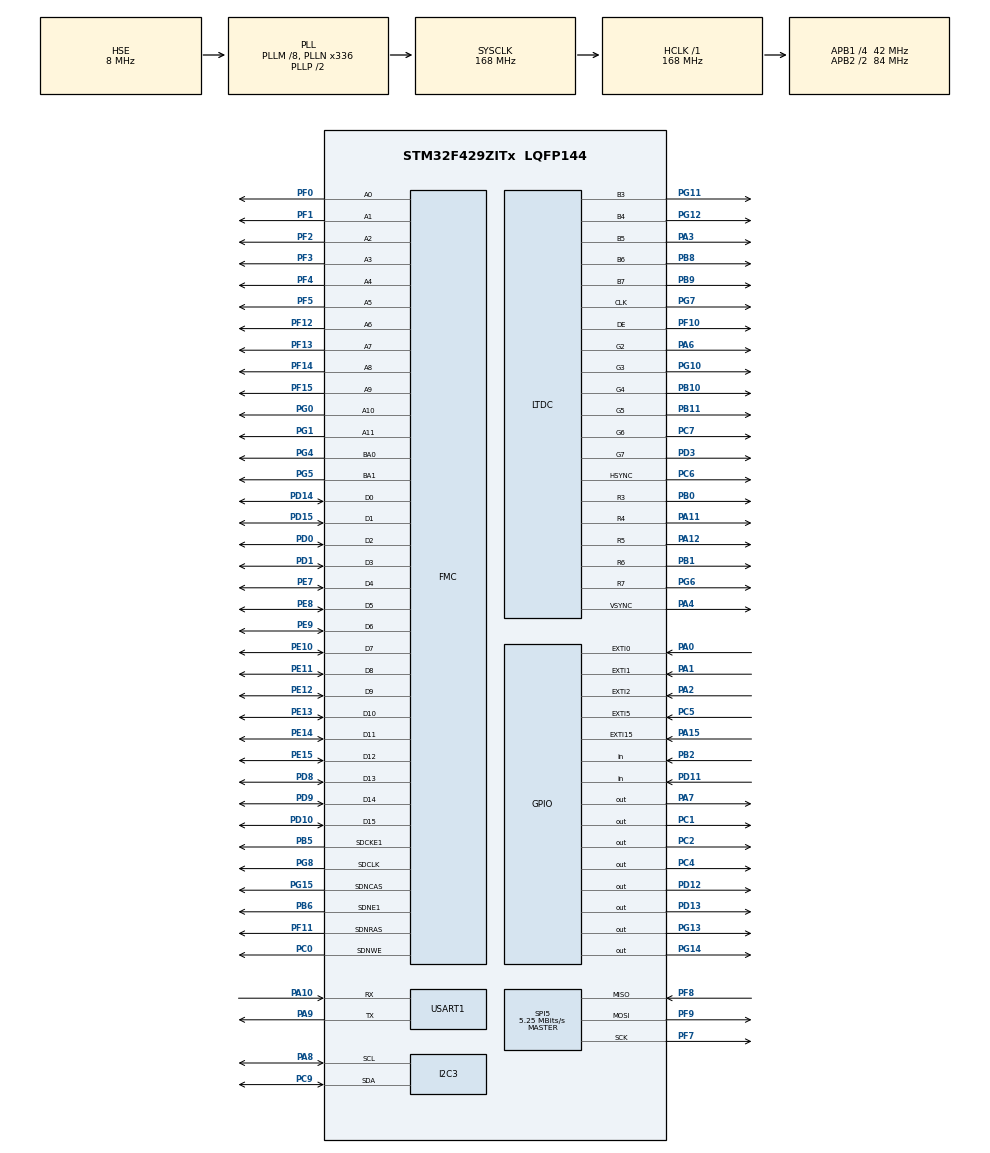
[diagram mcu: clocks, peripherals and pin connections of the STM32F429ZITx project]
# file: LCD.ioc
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DMA2D.ColorMode=DMA2D_OUTPUT_RGB565
FMC.CASLatency1=FMC_SDRAM_CAS_LATENCY_3
FMC.ExitSelfRefreshDelay1=7
FMC.LoadToActiveDelay1=2
FMC.RCDDelay1=2
FMC.RPDelay1=2
FMC.RPDelay2=2
FMC.ReadPipeDelay1=FMC_SDRAM_RPIPE_DELAY_1
FMC.ReadPipeDelay2=FMC_SDRAM_RPIPE_DELAY_1
FMC.RowCycleDelay1=7
FMC.RowCycleDelay2=7
FMC.SDClockPeriod1=FMC_SDRAM_CLOCK_PERIOD_2
FMC.SDClockPeriod2=FMC_SDRAM_CLOCK_PERIOD_2
FMC.SelfRefreshTime1=4
FMC.WriteRecoveryTime1=3
I2C3.Analog_Filter=I2C_ANALOGFILTER_DISABLE
LTDC.ActiveH=320
LTDC.ActiveW=240
LTDC.Alpha_L0=255
LTDC.HBP=20
LTDC.HFP=10
LTDC.HSync=10
LTDC.ImageHeight_L0=320
LTDC.ImageWidth_L0=240
LTDC.Layers=0
LTDC.PixelFormat_L0=LTDC_PIXEL_FORMAT_RGB565
LTDC.PixelFormat_L1=LTDC_PIXEL_FORMAT_RGB565
LTDC.VFP=4
LTDC.VSync=2
LTDC.WindowX0_L0=0
LTDC.WindowX1_L0=240
LTDC.WindowY0_L0=0
LTDC.WindowY1_L0=320
Mcu.Family=STM32F4
Mcu.Name=STM32F429ZITx
Mcu.Package=LQFP144
NVIC.DMA2D_IRQn=true\:0\:0\:false\:false\:true\:true\:true
NVIC.LTDC_IRQn=true\:0\:0\:false\:false\:true\:true\:true
NVIC.PriorityGroup=NVIC_PRIORITYGROUP_4
NVIC.TIM6_DAC_IRQn=true\:0\:0\:false\:false\:true\:false\:true
NVIC.TimeBase=TIM6_DAC_IRQn
NVIC.TimeBaseIP=TIM6
NVIC.USART1_IRQn=true\:0\:0\:false\:false\:true\:true\:true
PA0/WKUP.GPIO_ModeDefaultEXTI=GPIO_MODE_IT_RISING
PA0/WKUP.GPIO_PuPd=GPIO_NOPULL
PA0/WKUP.Signal=GPXTI0
PA1.GPIO_ModeDefaultEXTI=GPIO_MODE_IT_RISING
PA1.GPIO_PuPd=GPIO_NOPULL
PA1.Signal=GPXTI1
PA10.GPIO_ModeDefaultPP=GPIO_MODE_AF_PP
PA10.GPIO_PuPd=GPIO_NOPULL
PA10.GPIO_Speed=GPIO_SPEED_FREQ_VERY_HIGH
PA10.Mode=Asynchronous
PA10.Signal=USART1_RX
PA11.GPIO_Mode=GPIO_MODE_AF_PP
PA11.GPIO_PuPd=GPIO_NOPULL
PA11.GPIO_Speed=GPIO_SPEED_FREQ_LOW
PA11.Mode=RGB565
PA11.Signal=LTDC_R4
PA12.GPIO_Mode=GPIO_MODE_AF_PP
PA12.GPIO_PuPd=GPIO_NOPULL
PA12.GPIO_Speed=GPIO_SPEED_FREQ_LOW
PA12.Mode=RGB565
PA12.Signal=LTDC_R5
PA13.Signal=SYS_JTMS-SWDIO
PA14.Signal=SYS_JTCK-SWCLK
PA15.GPIO_ModeDefaultEXTI=GPIO_MODE_IT_RISING
PA15.GPIO_PuPd=GPIO_NOPULL
PA15.Signal=GPXTI15
PA2.GPIO_ModeDefaultEXTI=GPIO_MODE_IT_RISING
PA2.GPIO_PuPd=GPIO_NOPULL
PA2.Signal=GPXTI2
PA3.GPIO_Mode=GPIO_MODE_AF_PP
PA3.GPIO_PuPd=GPIO_NOPULL
PA3.GPIO_Speed=GPIO_SPEED_FREQ_LOW
PA3.Mode=RGB565
PA3.Signal=LTDC_B5
PA4.GPIO_Mode=GPIO_MODE_AF_PP
PA4.GPIO_PuPd=GPIO_NOPULL
PA4.GPIO_Speed=GPIO_SPEED_FREQ_LOW
PA4.Mode=RGB565
PA4.Signal=LTDC_VSYNC
PA6.GPIO_Mode=GPIO_MODE_AF_PP
PA6.GPIO_PuPd=GPIO_NOPULL
PA6.GPIO_Speed=GPIO_SPEED_FREQ_LOW
PA6.Mode=RGB565
PA6.Signal=LTDC_G2
PA7.GPIO_Mode=GPIO_MODE_OUTPUT_PP
PA7.GPIO_ModeDefaultOutputPP=GPIO_MODE_OUTPUT_PP
PA7.GPIO_PuPd=GPIO_NOPULL
PA7.GPIO_Speed=GPIO_SPEED_FREQ_LOW
PA7.PinState=GPIO_PIN_RESET
PA7.Signal=GPIO_Output
PA8.GPIO_Mode=GPIO_MODE_AF_OD
PA8.GPIO_PuPd=GPIO_NOPULL
PA8.GPIO_PuPdOD=GPIO_PULLUP
PA8.GPIO_Speed=GPIO_SPEED_FREQ_VERY_HIGH
PA8.Mode=I2C
PA8.Signal=I2C3_SCL
PA9.GPIO_ModeDefaultPP=GPIO_MODE_AF_PP
PA9.GPIO_PuPd=GPIO_NOPULL
PA9.GPIO_Speed=GPIO_SPEED_FREQ_VERY_HIGH
PA9.Mode=Asynchronous
PA9.Signal=USART1_TX
PB0.GPIO_Mode=GPIO_MODE_AF_PP
PB0.GPIO_PuPd=GPIO_NOPULL
PB0.GPIO_Speed=GPIO_SPEED_FREQ_LOW
PB0.Mode=RGB565
PB0.Signal=LTDC_R3
PB1.GPIO_Mode=GPIO_MODE_AF_PP
PB1.GPIO_PuPd=GPIO_NOPULL
PB1.GPIO_Speed=GPIO_SPEED_FREQ_LOW
PB1.Mode=RGB565
PB1.Signal=LTDC_R6
PB10.GPIO_Mode=GPIO_MODE_AF_PP
PB10.GPIO_PuPd=GPIO_NOPULL
PB10.GPIO_Speed=GPIO_SPEED_FREQ_LOW
PB10.Mode=RGB565
PB10.Signal=LTDC_G4
PB11.GPIO_Mode=GPIO_MODE_AF_PP
PB11.GPIO_PuPd=GPIO_NOPULL
PB11.GPIO_Speed=GPIO_SPEED_FREQ_LOW
PB11.Mode=RGB565
PB11.Signal=LTDC_G5
PB12.GPIO_Mode=GPIO_MODE_AF_PP
PB12.GPIO_PuPd=GPIO_NOPULL
PB12.GPIO_Speed=GPIO_SPEED_FREQ_VERY_HIGH
PB12.Signal=USB_OTG_HS_ID
PB13.GPIO_Mode=GPIO_MODE_INPUT
PB13.GPIO_PuPd=GPIO_NOPULL
PB13.Signal=USB_OTG_HS_VBUS
PB14.GPIO_Mode=GPIO_MODE_AF_PP
PB14.GPIO_PuPd=GPIO_NOPULL
PB14.GPIO_Speed=GPIO_SPEED_FREQ_VERY_HIGH
PB14.Signal=USB_OTG_HS_DM
PB15.GPIO_Mode=GPIO_MODE_AF_PP
PB15.GPIO_PuPd=GPIO_NOPULL
PB15.GPIO_Speed=GPIO_SPEED_FREQ_VERY_HIGH
PB15.Signal=USB_OTG_HS_DP
PB2/BOOT1.GPIO_Mode=GPIO_MODE_INPUT
PB2/BOOT1.GPIO_PuPd=GPIO_NOPULL
PB2/BOOT1.Signal=GPIO_Input
PB5.GPIO_Mode=GPIO_MODE_AF_PP
PB5.GPIO_PuPd=GPIO_NOPULL
PB5.GPIO_Speed=GPIO_SPEED_FREQ_VERY_HIGH
PB5.GPIO_Speed_High_Default=GPIO_SPEED_FREQ_VERY_HIGH
PB5.Mode=SdramChipSelect2_1
PB5.Signal=FMC_SDCKE1
PB6.GPIO_Mode=GPIO_MODE_AF_PP
PB6.GPIO_PuPd=GPIO_NOPULL
PB6.GPIO_Speed=GPIO_SPEED_FREQ_VERY_HIGH
PB6.GPIO_Speed_High_Default=GPIO_SPEED_FREQ_VERY_HIGH
PB6.Mode=SdramChipSelect2_1
PB6.Signal=FMC_SDNE1
PB8.GPIO_Mode=GPIO_MODE_AF_PP
PB8.GPIO_PuPd=GPIO_NOPULL
PB8.GPIO_Speed=GPIO_SPEED_FREQ_LOW
PB8.Mode=RGB565
PB8.Signal=LTDC_B6
PB9.GPIO_Mode=GPIO_MODE_AF_PP
PB9.GPIO_PuPd=GPIO_NOPULL
PB9.GPIO_Speed=GPIO_SPEED_FREQ_LOW
PB9.Mode=RGB565
PB9.Signal=LTDC_B7
PC0.GPIO_Mode=GPIO_MODE_AF_PP
PC0.GPIO_PuPd=GPIO_NOPULL
PC0.GPIO_Speed=GPIO_SPEED_FREQ_VERY_HIGH
PC0.GPIO_Speed_High_Default=GPIO_SPEED_FREQ_VERY_HIGH
PC0.Signal=FMC_SDNWE
PC1.GPIO_Mode=GPIO_MODE_OUTPUT_PP
PC1.GPIO_ModeDefaultOutputPP=GPIO_MODE_OUTPUT_PP
PC1.GPIO_PuPd=GPIO_NOPULL
PC1.GPIO_Speed=GPIO_SPEED_FREQ_LOW
PC1.PinState=GPIO_PIN_RESET
PC1.Signal=GPIO_Output
PC10.GPIO_Mode=GPIO_MODE_AF_PP
PC10.GPIO_PuPd=GPIO_NOPULL
PC10.GPIO_Speed=GPIO_SPEED_FREQ_LOW
PC10.Signal=LTDC_R2
PC14/OSC32_IN.Signal=RCC_OSC32_IN
PC15/OSC32_OUT.Signal=RCC_OSC32_OUT
PC2.GPIO_Mode=GPIO_MODE_OUTPUT_PP
PC2.GPIO_ModeDefaultOutputPP=GPIO_MODE_OUTPUT_PP
PC2.GPIO_PuPd=GPIO_NOPULL
PC2.GPIO_Speed=GPIO_SPEED_FREQ_LOW
PC2.PinState=GPIO_PIN_RESET
PC2.Signal=GPIO_Output
PC4.GPIO_Mode=GPIO_MODE_OUTPUT_PP
PC4.GPIO_ModeDefaultOutputPP=GPIO_MODE_OUTPUT_PP
PC4.GPIO_PuPd=GPIO_NOPULL
PC4.GPIO_Speed=GPIO_SPEED_FREQ_LOW
PC4.PinState=GPIO_PIN_RESET
PC4.Signal=GPIO_Output
PC5.GPIO_ModeDefaultEXTI=GPIO_MODE_IT_RISING
PC5.GPIO_PuPd=GPIO_NOPULL
PC5.Signal=GPXTI5
PC6.GPIO_Mode=GPIO_MODE_AF_PP
PC6.GPIO_PuPd=GPIO_NOPULL
PC6.GPIO_Speed=GPIO_SPEED_FREQ_LOW
PC6.Mode=RGB565
PC6.Signal=LTDC_HSYNC
PC7.GPIO_Mode=GPIO_MODE_AF_PP
PC7.GPIO_PuPd=GPIO_NOPULL
PC7.GPIO_Speed=GPIO_SPEED_FREQ_LOW
PC7.Mode=RGB565
PC7.Signal=LTDC_G6
PC9.GPIO_Mode=GPIO_MODE_AF_OD
PC9.GPIO_PuPd=GPIO_NOPULL
PC9.GPIO_PuPdOD=GPIO_PULLUP
PC9.GPIO_Speed=GPIO_SPEED_FREQ_VERY_HIGH
PC9.Mode=I2C
PC9.Signal=I2C3_SDA
PD0.GPIO_Mode=GPIO_MODE_AF_PP
PD0.GPIO_PuPd=GPIO_NOPULL
PD0.GPIO_Speed=GPIO_SPEED_FREQ_VERY_HIGH
PD0.GPIO_Speed_High_Default=GPIO_SPEED_FREQ_VERY_HIGH
PD0.Signal=FMC_D2_DA2
PD1.GPIO_Mode=GPIO_MODE_AF_PP
PD1.GPIO_PuPd=GPIO_NOPULL
PD1.GPIO_Speed=GPIO_SPEED_FREQ_VERY_HIGH
PD1.GPIO_Speed_High_Default=GPIO_SPEED_FREQ_VERY_HIGH
PD1.Signal=FMC_D3_DA3
PD10.GPIO_Mode=GPIO_MODE_AF_PP
PD10.GPIO_PuPd=GPIO_NOPULL
PD10.GPIO_Speed=GPIO_SPEED_FREQ_VERY_HIGH
PD10.GPIO_Speed_High_Default=GPIO_SPEED_FREQ_VERY_HIGH
PD10.Signal=FMC_D15_DA15
PD11.GPIO_Mode=GPIO_MODE_INPUT
PD11.GPIO_PuPd=GPIO_NOPULL
PD11.Signal=GPIO_Input
PD12.GPIO_Mode=GPIO_MODE_OUTPUT_PP
PD12.GPIO_ModeDefaultOutputPP=GPIO_MODE_OUTPUT_PP
PD12.GPIO_PuPd=GPIO_NOPULL
PD12.GPIO_Speed=GPIO_SPEED_FREQ_LOW
PD12.PinState=GPIO_PIN_RESET
PD12.Signal=GPIO_Output
PD13.GPIO_Mode=GPIO_MODE_OUTPUT_PP
PD13.GPIO_ModeDefaultOutputPP=GPIO_MODE_OUTPUT_PP
PD13.GPIO_PuPd=GPIO_NOPULL
PD13.GPIO_Speed=GPIO_SPEED_FREQ_LOW
PD13.PinState=GPIO_PIN_RESET
PD13.Signal=GPIO_Output
PD14.GPIO_Mode=GPIO_MODE_AF_PP
PD14.GPIO_PuPd=GPIO_NOPULL
PD14.GPIO_Speed=GPIO_SPEED_FREQ_VERY_HIGH
PD14.GPIO_Speed_High_Default=GPIO_SPEED_FREQ_VERY_HIGH
PD14.Signal=FMC_D0_DA0
PD15.GPIO_Mode=GPIO_MODE_AF_PP
PD15.GPIO_PuPd=GPIO_NOPULL
PD15.GPIO_Speed=GPIO_SPEED_FREQ_VERY_HIGH
PD15.GPIO_Speed_High_Default=GPIO_SPEED_FREQ_VERY_HIGH
PD15.Signal=FMC_D1_DA1
PD3.GPIO_Mode=GPIO_MODE_AF_PP
PD3.GPIO_PuPd=GPIO_NOPULL
PD3.GPIO_Speed=GPIO_SPEED_FREQ_LOW
PD3.Mode=RGB565
PD3.Signal=LTDC_G7
PD6.GPIO_Mode=GPIO_MODE_AF_PP
PD6.GPIO_PuPd=GPIO_NOPULL
PD6.GPIO_Speed=GPIO_SPEED_FREQ_LOW
PD6.Signal=LTDC_B2
PD8.GPIO_Mode=GPIO_MODE_AF_PP
PD8.GPIO_PuPd=GPIO_NOPULL
PD8.GPIO_Speed=GPIO_SPEED_FREQ_VERY_HIGH
PD8.GPIO_Speed_High_Default=GPIO_SPEED_FREQ_VERY_HIGH
PD8.Signal=FMC_D13_DA13
PD9.GPIO_Mode=GPIO_MODE_AF_PP
PD9.GPIO_PuPd=GPIO_NOPULL
PD9.GPIO_Speed=GPIO_SPEED_FREQ_VERY_HIGH
PD9.GPIO_Speed_High_Default=GPIO_SPEED_FREQ_VERY_HIGH
PD9.Signal=FMC_D14_DA14
PE0.GPIO_Mode=GPIO_MODE_AF_PP
PE0.GPIO_PuPd=GPIO_NOPULL
PE0.GPIO_Speed=GPIO_SPEED_FREQ_VERY_HIGH
PE0.GPIO_Speed_High_Default=GPIO_SPEED_FREQ_VERY_HIGH
PE0.Signal=FMC_NBL0
PE1.GPIO_Mode=GPIO_MODE_AF_PP
PE1.GPIO_PuPd=GPIO_NOPULL
PE1.GPIO_Speed=GPIO_SPEED_FREQ_VERY_HIGH
PE1.GPIO_Speed_High_Default=GPIO_SPEED_FREQ_VERY_HIGH
PE1.Signal=FMC_NBL1
PE10.GPIO_Mode=GPIO_MODE_AF_PP
PE10.GPIO_PuPd=GPIO_NOPULL
PE10.GPIO_Speed=GPIO_SPEED_FREQ_VERY_HIGH
PE10.GPIO_Speed_High_Default=GPIO_SPEED_FREQ_VERY_HIGH
PE10.Signal=FMC_D7_DA7
PE11.GPIO_Mode=GPIO_MODE_AF_PP
PE11.GPIO_PuPd=GPIO_NOPULL
PE11.GPIO_Speed=GPIO_SPEED_FREQ_VERY_HIGH
PE11.GPIO_Speed_High_Default=GPIO_SPEED_FREQ_VERY_HIGH
PE11.Signal=FMC_D8_DA8
PE12.GPIO_Mode=GPIO_MODE_AF_PP
PE12.GPIO_PuPd=GPIO_NOPULL
PE12.GPIO_Speed=GPIO_SPEED_FREQ_VERY_HIGH
PE12.GPIO_Speed_High_Default=GPIO_SPEED_FREQ_VERY_HIGH
PE12.Signal=FMC_D9_DA9
PE13.GPIO_Mode=GPIO_MODE_AF_PP
PE13.GPIO_PuPd=GPIO_NOPULL
PE13.GPIO_Speed=GPIO_SPEED_FREQ_VERY_HIGH
PE13.GPIO_Speed_High_Default=GPIO_SPEED_FREQ_VERY_HIGH
PE13.Signal=FMC_D10_DA10
PE14.GPIO_Mode=GPIO_MODE_AF_PP
PE14.GPIO_PuPd=GPIO_NOPULL
PE14.GPIO_Speed=GPIO_SPEED_FREQ_VERY_HIGH
PE14.GPIO_Speed_High_Default=GPIO_SPEED_FREQ_VERY_HIGH
PE14.Signal=FMC_D11_DA11
PE15.GPIO_Mode=GPIO_MODE_AF_PP
PE15.GPIO_PuPd=GPIO_NOPULL
PE15.GPIO_Speed=GPIO_SPEED_FREQ_VERY_HIGH
PE15.GPIO_Speed_High_Default=GPIO_SPEED_FREQ_VERY_HIGH
PE15.Signal=FMC_D12_DA12
PE7.GPIO_Mode=GPIO_MODE_AF_PP
PE7.GPIO_PuPd=GPIO_NOPULL
PE7.GPIO_Speed=GPIO_SPEED_FREQ_VERY_HIGH
PE7.GPIO_Speed_High_Default=GPIO_SPEED_FREQ_VERY_HIGH
PE7.Signal=FMC_D4_DA4
PE8.GPIO_Mode=GPIO_MODE_AF_PP
PE8.GPIO_PuPd=GPIO_NOPULL
PE8.GPIO_Speed=GPIO_SPEED_FREQ_VERY_HIGH
PE8.GPIO_Speed_High_Default=GPIO_SPEED_FREQ_VERY_HIGH
PE8.Signal=FMC_D5_DA5
PE9.GPIO_Mode=GPIO_MODE_AF_PP
PE9.GPIO_PuPd=GPIO_NOPULL
PE9.GPIO_Speed=GPIO_SPEED_FREQ_VERY_HIGH
PE9.GPIO_Speed_High_Default=GPIO_SPEED_FREQ_VERY_HIGH
PE9.Signal=FMC_D6_DA6
PF0.GPIO_Mode=GPIO_MODE_AF_PP
PF0.GPIO_PuPd=GPIO_NOPULL
PF0.GPIO_Speed=GPIO_SPEED_FREQ_VERY_HIGH
PF0.GPIO_Speed_High_Default=GPIO_SPEED_FREQ_VERY_HIGH
PF0.Signal=FMC_A0
PF1.GPIO_Mode=GPIO_MODE_AF_PP
PF1.GPIO_PuPd=GPIO_NOPULL
PF1.GPIO_Speed=GPIO_SPEED_FREQ_VERY_HIGH
PF1.GPIO_Speed_High_Default=GPIO_SPEED_FREQ_VERY_HIGH
PF1.Signal=FMC_A1
PF10.GPIO_Mode=GPIO_MODE_AF_PP
PF10.GPIO_PuPd=GPIO_NOPULL
PF10.GPIO_Speed=GPIO_SPEED_FREQ_LOW
PF10.Mode=RGB565
PF10.Signal=LTDC_DE
PF11.GPIO_Mode=GPIO_MODE_AF_PP
PF11.GPIO_PuPd=GPIO_NOPULL
PF11.GPIO_Speed=GPIO_SPEED_FREQ_VERY_HIGH
PF11.GPIO_Speed_High_Default=GPIO_SPEED_FREQ_VERY_HIGH
PF11.Signal=FMC_SDNRAS
PF12.GPIO_Mode=GPIO_MODE_AF_PP
PF12.GPIO_PuPd=GPIO_NOPULL
PF12.GPIO_Speed=GPIO_SPEED_FREQ_VERY_HIGH
PF12.GPIO_Speed_High_Default=GPIO_SPEED_FREQ_VERY_HIGH
PF12.Signal=FMC_A6
PF13.GPIO_Mode=GPIO_MODE_AF_PP
PF13.GPIO_PuPd=GPIO_NOPULL
PF13.GPIO_Speed=GPIO_SPEED_FREQ_VERY_HIGH
PF13.GPIO_Speed_High_Default=GPIO_SPEED_FREQ_VERY_HIGH
PF13.Signal=FMC_A7
PF14.GPIO_Mode=GPIO_MODE_AF_PP
PF14.GPIO_PuPd=GPIO_NOPULL
PF14.GPIO_Speed=GPIO_SPEED_FREQ_VERY_HIGH
PF14.GPIO_Speed_High_Default=GPIO_SPEED_FREQ_VERY_HIGH
PF14.Signal=FMC_A8
PF15.GPIO_Mode=GPIO_MODE_AF_PP
PF15.GPIO_PuPd=GPIO_NOPULL
PF15.GPIO_Speed=GPIO_SPEED_FREQ_VERY_HIGH
PF15.GPIO_Speed_High_Default=GPIO_SPEED_FREQ_VERY_HIGH
PF15.Signal=FMC_A9
PF2.GPIO_Mode=GPIO_MODE_AF_PP
PF2.GPIO_PuPd=GPIO_NOPULL
PF2.GPIO_Speed=GPIO_SPEED_FREQ_VERY_HIGH
PF2.GPIO_Speed_High_Default=GPIO_SPEED_FREQ_VERY_HIGH
PF2.Signal=FMC_A2
PF3.GPIO_Mode=GPIO_MODE_AF_PP
PF3.GPIO_PuPd=GPIO_NOPULL
PF3.GPIO_Speed=GPIO_SPEED_FREQ_VERY_HIGH
PF3.GPIO_Speed_High_Default=GPIO_SPEED_FREQ_VERY_HIGH
PF3.Signal=FMC_A3
PF4.GPIO_Mode=GPIO_MODE_AF_PP
PF4.GPIO_PuPd=GPIO_NOPULL
PF4.GPIO_Speed=GPIO_SPEED_FREQ_VERY_HIGH
PF4.GPIO_Speed_High_Default=GPIO_SPEED_FREQ_VERY_HIGH
PF4.Signal=FMC_A4
PF5.GPIO_Mode=GPIO_MODE_AF_PP
PF5.GPIO_PuPd=GPIO_NOPULL
PF5.GPIO_Speed=GPIO_SPEED_FREQ_VERY_HIGH
PF5.GPIO_Speed_High_Default=GPIO_SPEED_FREQ_VERY_HIGH
PF5.Signal=FMC_A5
PF7.GPIO_Mode=GPIO_MODE_AF_PP
PF7.GPIO_PuPd=GPIO_NOPULL
PF7.GPIO_Speed=GPIO_SPEED_FREQ_VERY_HIGH
PF7.Mode=Full_Duplex_Master
PF7.Signal=SPI5_SCK
PF8.GPIO_Mode=GPIO_MODE_AF_PP
PF8.GPIO_PuPd=GPIO_NOPULL
PF8.GPIO_Speed=GPIO_SPEED_FREQ_VERY_HIGH
PF8.Mode=Full_Duplex_Master
PF8.Signal=SPI5_MISO
PF9.GPIO_Mode=GPIO_MODE_AF_PP
PF9.GPIO_PuPd=GPIO_NOPULL
PF9.GPIO_Speed=GPIO_SPEED_FREQ_VERY_HIGH
PF9.Mode=Full_Duplex_Master
PF9.Signal=SPI5_MOSI
PG0.GPIO_Mode=GPIO_MODE_AF_PP
PG0.GPIO_PuPd=GPIO_NOPULL
PG0.GPIO_Speed=GPIO_SPEED_FREQ_VERY_HIGH
PG0.GPIO_Speed_High_Default=GPIO_SPEED_FREQ_VERY_HIGH
PG0.Signal=FMC_A10
PG1.GPIO_Mode=GPIO_MODE_AF_PP
PG1.GPIO_PuPd=GPIO_NOPULL
PG1.GPIO_Speed=GPIO_SPEED_FREQ_VERY_HIGH
PG1.GPIO_Speed_High_Default=GPIO_SPEED_FREQ_VERY_HIGH
PG1.Signal=FMC_A11
PG10.GPIO_Mode=GPIO_MODE_AF_PP
PG10.GPIO_PuPd=GPIO_NOPULL
PG10.GPIO_Speed=GPIO_SPEED_FREQ_LOW
PG10.Mode=RGB565
PG10.Signal=LTDC_G3
PG11.GPIO_Mode=GPIO_MODE_AF_PP
PG11.GPIO_PuPd=GPIO_NOPULL
PG11.GPIO_Speed=GPIO_SPEED_FREQ_LOW
PG11.Mode=RGB565
PG11.Signal=LTDC_B3
PG12.GPIO_Mode=GPIO_MODE_AF_PP
PG12.GPIO_PuPd=GPIO_NOPULL
PG12.GPIO_Speed=GPIO_SPEED_FREQ_LOW
PG12.Mode=RGB565
PG12.Signal=LTDC_B4
PG13.GPIO_Mode=GPIO_MODE_OUTPUT_PP
PG13.GPIO_ModeDefaultOutputPP=GPIO_MODE_OUTPUT_PP
PG13.GPIO_PuPd=GPIO_NOPULL
PG13.GPIO_Speed=GPIO_SPEED_FREQ_LOW
PG13.PinState=GPIO_PIN_RESET
PG13.Signal=GPIO_Output
PG14.GPIO_Mode=GPIO_MODE_OUTPUT_PP
PG14.GPIO_ModeDefaultOutputPP=GPIO_MODE_OUTPUT_PP
PG14.GPIO_PuPd=GPIO_NOPULL
PG14.GPIO_Speed=GPIO_SPEED_FREQ_LOW
PG14.PinState=GPIO_PIN_RESET
PG14.Signal=GPIO_Output
PG15.GPIO_Mode=GPIO_MODE_AF_PP
PG15.GPIO_PuPd=GPIO_NOPULL
PG15.GPIO_Speed=GPIO_SPEED_FREQ_VERY_HIGH
PG15.GPIO_Speed_High_Default=GPIO_SPEED_FREQ_VERY_HIGH
PG15.Signal=FMC_SDNCAS
PG4.GPIO_Mode=GPIO_MODE_AF_PP
PG4.GPIO_PuPd=GPIO_NOPULL
PG4.GPIO_Speed=GPIO_SPEED_FREQ_VERY_HIGH
PG4.GPIO_Speed_High_Default=GPIO_SPEED_FREQ_VERY_HIGH
PG4.Signal=FMC_A14_BA0
PG5.GPIO_Mode=GPIO_MODE_AF_PP
PG5.GPIO_PuPd=GPIO_NOPULL
PG5.GPIO_Speed=GPIO_SPEED_FREQ_VERY_HIGH
PG5.GPIO_Speed_High_Default=GPIO_SPEED_FREQ_VERY_HIGH
PG5.Signal=FMC_A15_BA1
PG6.GPIO_Mode=GPIO_MODE_AF_PP
PG6.GPIO_PuPd=GPIO_NOPULL
PG6.GPIO_Speed=GPIO_SPEED_FREQ_LOW
PG6.Mode=RGB565
PG6.Signal=LTDC_R7
PG7.GPIO_Mode=GPIO_MODE_AF_PP
PG7.GPIO_PuPd=GPIO_NOPULL
PG7.GPIO_Speed=GPIO_SPEED_FREQ_LOW
PG7.Mode=RGB565
PG7.Signal=LTDC_CLK
PG8.GPIO_Mode=GPIO_MODE_AF_PP
PG8.GPIO_PuPd=GPIO_NOPULL
PG8.GPIO_Speed=GPIO_SPEED_FREQ_VERY_HIGH
PG8.GPIO_Speed_High_Default=GPIO_SPEED_FREQ_VERY_HIGH
PG8.Signal=FMC_SDCLK
PH0/OSC_IN.Mode=HSE-External-Oscillator
PH0/OSC_IN.Signal=RCC_OSC_IN
PH1/OSC_OUT.Mode=HSE-External-Oscillator
PH1/OSC_OUT.Signal=RCC_OSC_OUT
ProjectManager.HeapSize=0x200
ProjectManager.StackSize=0x400
ProjectManager.TargetToolchain=MDK-ARM V5.27
RCC.48MHZClocksFreq_Value=67200000
RCC.AHBFreq_Value=168000000
RCC.APB1CLKDivider=RCC_HCLK_DIV4
RCC.APB1Freq_Value=42000000
RCC.APB1TimFreq_Value=84000000
RCC.APB2CLKDivider=RCC_HCLK_DIV2
RCC.APB2Freq_Value=84000000
RCC.APB2TimFreq_Value=168000000
RCC.CortexFreq_Value=168000000
RCC.HCLKFreq_Value=168000000
RCC.HSE_VALUE=8000000
RCC.HSI_VALUE=16000000
RCC.LSE_VALUE=32768
RCC.PLLM=8
RCC.PLLN=336
RCC.PLLQ=5
RCC.PLLSAIN=192
RCC.PLLSourceVirtual=RCC_PLLSOURCE_HSE
RCC.SYSCLKFreq_VALUE=168000000
RCC.SYSCLKSource=RCC_SYSCLKSOURCE_PLLCLK
RCC.VCOOutputFreq_Value=336000000
SH.FMC_A0.0=FMC_A0,12b-sda1
SH.FMC_A1.0=FMC_A1,12b-sda1
SH.FMC_A10.0=FMC_A10,12b-sda1
SH.FMC_A11.0=FMC_A11,12b-sda1
SH.FMC_A14_BA0.0=FMC_BA0,FourSdramBanks1
SH.FMC_A15_BA1.0=FMC_BA1,FourSdramBanks1
SH.FMC_A2.0=FMC_A2,12b-sda1
SH.FMC_A3.0=FMC_A3,12b-sda1
SH.FMC_A4.0=FMC_A4,12b-sda1
SH.FMC_A5.0=FMC_A5,12b-sda1
SH.FMC_A6.0=FMC_A6,12b-sda1
SH.FMC_A7.0=FMC_A7,12b-sda1
SH.FMC_A8.0=FMC_A8,12b-sda1
SH.FMC_A9.0=FMC_A9,12b-sda1
SH.FMC_D0_DA0.0=FMC_D0,sd-16b-d1
SH.FMC_D10_DA10.0=FMC_D10,sd-16b-d1
SH.FMC_D11_DA11.0=FMC_D11,sd-16b-d1
SH.FMC_D12_DA12.0=FMC_D12,sd-16b-d1
SH.FMC_D13_DA13.0=FMC_D13,sd-16b-d1
SH.FMC_D14_DA14.0=FMC_D14,sd-16b-d1
SH.FMC_D15_DA15.0=FMC_D15,sd-16b-d1
SH.FMC_D1_DA1.0=FMC_D1,sd-16b-d1
SH.FMC_D2_DA2.0=FMC_D2,sd-16b-d1
SH.FMC_D3_DA3.0=FMC_D3,sd-16b-d1
SH.FMC_D4_DA4.0=FMC_D4,sd-16b-d1
SH.FMC_D5_DA5.0=FMC_D5,sd-16b-d1
SH.FMC_D6_DA6.0=FMC_D6,sd-16b-d1
SH.FMC_D7_DA7.0=FMC_D7,sd-16b-d1
SH.FMC_D8_DA8.0=FMC_D8,sd-16b-d1
SH.FMC_D9_DA9.0=FMC_D9,sd-16b-d1
SH.FMC_NBL0.0=FMC_NBL0
SH.FMC_NBL1.0=FMC_NBL1
SH.FMC_SDCLK.0=FMC_SDCLK,12b-sda1
SH.FMC_SDNCAS.0=FMC_SDNCAS,12b-sda1
SH.FMC_SDNRAS.0=FMC_SDNRAS,12b-sda1
SH.FMC_SDNWE.0=FMC_SDNWE,12b-sda1
SPI5.BaudRatePrescaler=SPI_BAUDRATEPRESCALER_16
SPI5.CalculateBaudRate=5.25 MBits/s
SPI5.Direction=SPI_DIRECTION_2LINES
SPI5.Mode=SPI_MODE_MASTER
SPI5.VirtualType=VM_MASTER
USART1.VirtualMode=VM_ASYNC
VP_DMA2D_VS_DMA2D.Mode=DMA2D_Activate
VP_SYS_VS_tim6.Mode=TIM6
VP_TIM1_VS_ClockSourceINT.Mode=Internal
board=STM32F429I-DISC1

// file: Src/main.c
/* USER CODE BEGIN Header */
/**
  ******************************************************************************
  * @file           : main.c
  * @brief          : Main program body
  ******************************************************************************
  * @attention
  *
  * <h2><center>&copy; Copyright (c) 2020 STMicroelectronics.
  * All rights reserved.</center></h2>
  *
  * This software component is licensed by ST under Ultimate Liberty license
  * SLA0044, the "License"; You may not use this file except in compliance with
  * the License. You may obtain a copy of the License at:
  *                             www.st.com/SLA0044
  *
  ******************************************************************************
  */
/* USER CODE END Header */

#include "main.h"

/* USER CODE BEGIN Includes */
#include "stm32f429i_discovery_lcd.h"
#include "stm32f429i_discovery_sdram.h"
#include "stm32f429i_discovery_ts.h"
#include "stlogo.h"
#include "usv.h"
#include "tic_tac_toe.h"
#include <stdio.h>
#include <string.h>

/* USER CODE END Includes */

DMA2D_HandleTypeDef hdma2d;

I2C_HandleTypeDef hi2c3;

LTDC_HandleTypeDef hltdc;

SPI_HandleTypeDef hspi5;

TIM_HandleTypeDef htim1;

UART_HandleTypeDef huart1;

SDRAM_HandleTypeDef hsdram1;

void SystemClock_Config(void);
static void MX_GPIO_Init(void);
static void MX_DMA2D_Init(void);
static void MX_FMC_Init(void);
static void MX_I2C3_Init(void);
static void MX_LTDC_Init(void);
static void MX_SPI5_Init(void);
static void MX_TIM1_Init(void);
static void MX_USART1_UART_Init(void);

#include "stm32f429i_discovery_lcd.h"
#include "stm32f429i_discovery_sdram.h"
#define NUMAR_X 0
#define NUMAR_0 1
#define NO_PLAYER -1
int tryGetWinner(int board[3][3]);
void showGameScreen();
void Meniu_Credits();
void Meniu_Show();

int main(void)
{
  HAL_Init();
  SystemClock_Config();
  MX_GPIO_Init();
  MX_DMA2D_Init();
  MX_FMC_Init();
  MX_I2C3_Init();
  MX_LTDC_Init();
  MX_SPI5_Init();
  MX_TIM1_Init();
  MX_USART1_UART_Init();
	printf("\n\rLaborator-Proiect MICROCONTROLERE\n\r");
	BSP_LCD_Init();
  BSP_LCD_LayerDefaultInit(LCD_BACKGROUND_LAYER, LCD_FRAME_BUFFER);
	BSP_LCD_LayerDefaultInit(LCD_FOREGROUND_LAYER, LCD_FRAME_BUFFER);
  BSP_LCD_SelectLayer(LCD_FOREGROUND_LAYER);
  BSP_LCD_DisplayOn();
	BSP_LCD_Clear(BOARD_COLOR);
	BSP_LCD_SetTextColor(LCD_COLOR_RED);
	BSP_LCD_SetFont(&Font16);

	BSP_LCD_SetTextColor(LCD_COLOR_RED);

		if (BSP_TS_Init(BSP_LCD_GetXSize(), BSP_LCD_GetYSize()) == TS_ERROR) {
				BSP_LCD_DisplayStringAt(0, LINE(11), (uint8_t*)"Eroare initializare touch!", LEFT_MODE);
		}

		Meniu_Show();
}

void Meniu_Show()
{
	BSP_LCD_SetTextColor(LCD_COLOR_BLACK);

	BSP_LCD_Clear(0xffffffff);

		int xPosTouched;
		int yPosTouched;
while(1){
	BSP_LCD_DrawRect(56, 74, 130, 30);
	BSP_LCD_DisplayStringAt(71, 85, (uint8_t*)"Start Joc", LEFT_MODE);

	BSP_LCD_DrawRect(56, 128, 130, 30);
	BSP_LCD_DisplayStringAt(71, 140, (uint8_t*)"Machine", LEFT_MODE);

	BSP_LCD_DrawRect(56, 188, 130, 30);
	BSP_LCD_DisplayStringAt(71, 200, (uint8_t*)"Credits", LEFT_MODE);

	BSP_LCD_DrawRect(56, 240, 130, 30);
	BSP_LCD_DisplayStringAt(71, 250, (uint8_t*)"Exit", LEFT_MODE);
			HAL_Delay(50);

			BSP_TS_GetState(&TS_State);
		if(!TS_State.TouchDetected)  continue;

		xPosTouched = TS_State.X;
		yPosTouched = TS_State.Y;
			if(xPosTouched > 56
				&& xPosTouched < (56 + 130)
				&& yPosTouched > 85
				&& yPosTouched < (74 + 30))
			{
				showGameScreen();
			}
				if(xPosTouched > 56
				&& xPosTouched < (56 + 130)
				&& yPosTouched > 188
				&& yPosTouched < (188 + 30))

			{
				 Meniu_Credits();
			}

		}
}
void Meniu_Credits()
{
	BSP_LCD_Clear(0xffffffff);
	BSP_LCD_DisplayStringAt(56, 128, (uint8_t*)"Program realizat", LEFT_MODE);
	BSP_LCD_DisplayStringAt(56, 148, (uint8_t*)"de:", LEFT_MODE);
	BSP_LCD_DisplayStringAt(56, 188, (uint8_t*)"Vizitiu Valentin", LEFT_MODE);
	BSP_LCD_DisplayStringAt(56, 200, (uint8_t*)"Roman Petrica", LEFT_MODE);

	BSP_LCD_DrawRect(56, 250, 130, 30);
	BSP_LCD_DisplayStringAt(85, 250, (uint8_t*)"Return", LEFT_MODE);

	while(1){
			HAL_Delay(50);
	   int xPosTouched;
		 int yPosTouched;

			BSP_TS_GetState(&TS_State);
		if(!TS_State.TouchDetected)  continue;

		xPosTouched = TS_State.X;
		yPosTouched = TS_State.Y;
			if(xPosTouched > 56
				&& xPosTouched < (56 + 130)
				&& yPosTouched > 250
				&& yPosTouched < (250 + 30))
			{

			BSP_LCD_Clear(0xffffffff);
			break;
			}
	}
}

void showGameScreen()
{
		BSP_LCD_Clear(BOARD_COLOR);

		// text at the top of the LCD
		BSP_LCD_DisplayStringAt(0, LINE(1), (uint8_t*)"X si 0", CENTER_MODE);
		BSP_LCD_DrawRect(30, 30, CELL_SIZE * 3, CELL_SIZE * 3);

		int xPosTouched;
		int yPosTouched;
		DrawBoard(30, 30);

		int currentPlayer = NUMAR_X;
		int board[3][3] = {
			{-1, -1, -1},
			{-1, -1, -1},
			{-1, -1, -1}
		};

		int winner = NO_PLAYER;

	while (1)
  {
		HAL_Delay(50);

		BSP_TS_GetState(&TS_State);
		if(!TS_State.TouchDetected)  continue;

		if (winner != NO_PLAYER) break;

		xPosTouched = TS_State.X;
		yPosTouched = TS_State.Y;

		char buf[50];

		int cellPressed = TryGetCellTouched(xPosTouched, yPosTouched);

		if (cellPressed != -1)
		{
			struct CellIndexes ci = GetCellIndexes(cellPressed);

			// can't place in cell that already has a symbol in
			if (CellIsEmpty(cellPressed, board, ci) == 0) continue;

			board[ci.i][ci.j] = currentPlayer;

			if (currentPlayer == 0)
			{
				DrawXInsideCell(cellPressed);
			}
			else
			{
				DrawCircleInCell(cellPressed);
			}

			if (currentPlayer == 0)
				currentPlayer = 1;
			else
				currentPlayer = 0;

			winner = tryGetWinner(board);

			if (winner == NUMAR_X)
			{
				BSP_LCD_DisplayStringAt(20, LINE(16), (uint8_t*)"X WINNER", CENTER_MODE);
				HAL_Delay(500);
				continue;
			}
			else if (winner == NUMAR_0)
			{
				BSP_LCD_DisplayStringAt(20, LINE(16), (uint8_t*)"O WINNER", CENTER_MODE);
				HAL_Delay(500);
				continue;
			}

			sprintf(buf, "Apasat: %d", cellPressed);
			BSP_LCD_DisplayStringAt(20, LINE(15), (uint8_t*)buf, CENTER_MODE);

			sprintf(buf, "X: %d, Y: %d", xPosTouched, yPosTouched);
			BSP_LCD_DisplayStringAt(20, LINE(16), (uint8_t*)buf, CENTER_MODE);
		} // end if
	} // end while
	BSP_LCD_Clear(0xffffffff);
} // end func

// Tries to check if any player won
// RETURNS: 0 - X Player won, 1 - O Player won, -1 - No Player won
int tryGetWinner(int board[3][3])
{
	// orizontal
	for (int i = 0; i < 3; i++)
		if (board[i][0] != NO_PLAYER
				&& (board[i][0] == board[i][1])
				&& (board[i][1] == board[i][2]))
		{
			return board[i][0];
		}

	// vertical
	for (int j = 0; j < 3; j++)
		if (board[0][j] != NO_PLAYER
				&& (board[0][j] == board[1][j])
				&& (board[1][j] == board[2][j]))
			{
				return board[0][j];
			}

	// diagonala principala
	if (board[0][0] != NO_PLAYER
			&& (board[0][0] == board[1][1])
			&& (board[1][1] == board[2][2]))
		{
			return board[0][0];
		}

	// diagonala secundara
	if (board[0][2] != NO_PLAYER
			&& (board[0][2] == board[1][1])
			&& (board[1][1] == board[2][0]))
		{
			return board[0][2];
		}

	return NO_PLAYER;
}

void SystemClock_Config(void)
{
  RCC_OscInitTypeDef RCC_OscInitStruct = {0};
  RCC_ClkInitTypeDef RCC_ClkInitStruct = {0};
  RCC_PeriphCLKInitTypeDef PeriphClkInitStruct = {0};

  /** Configure the main internal regulator output voltage
  */
  __HAL_RCC_PWR_CLK_ENABLE();
  __HAL_PWR_VOLTAGESCALING_CONFIG(PWR_REGULATOR_VOLTAGE_SCALE1);
  /** Initializes the CPU, AHB and APB busses clocks
  */
  RCC_OscInitStruct.OscillatorType = RCC_OSCILLATORTYPE_HSE;
  RCC_OscInitStruct.HSEState = RCC_HSE_ON;
  RCC_OscInitStruct.PLL.PLLState = RCC_PLL_ON;
  RCC_OscInitStruct.PLL.PLLSource = RCC_PLLSOURCE_HSE;
  RCC_OscInitStruct.PLL.PLLM = 8;
  RCC_OscInitStruct.PLL.PLLN = 336;
  RCC_OscInitStruct.PLL.PLLP = RCC_PLLP_DIV2;
  RCC_OscInitStruct.PLL.PLLQ = 5;
  if (HAL_RCC_OscConfig(&RCC_OscInitStruct) != HAL_OK)
  {
    Error_Handler();
  }
  /** Initializes the CPU, AHB and APB busses clocks
  */
  RCC_ClkInitStruct.ClockType = RCC_CLOCKTYPE_HCLK|RCC_CLOCKTYPE_SYSCLK
                              |RCC_CLOCKTYPE_PCLK1|RCC_CLOCKTYPE_PCLK2;
  RCC_ClkInitStruct.SYSCLKSource = RCC_SYSCLKSOURCE_PLLCLK;
  RCC_ClkInitStruct.AHBCLKDivider = RCC_SYSCLK_DIV1;
  RCC_ClkInitStruct.APB1CLKDivider = RCC_HCLK_DIV4;
  RCC_ClkInitStruct.APB2CLKDivider = RCC_HCLK_DIV2;

  if (HAL_RCC_ClockConfig(&RCC_ClkInitStruct, FLASH_LATENCY_5) != HAL_OK)
  {
    Error_Handler();
  }
  PeriphClkInitStruct.PeriphClockSelection = RCC_PERIPHCLK_LTDC;
  PeriphClkInitStruct.PLLSAI.PLLSAIN = 192;
  PeriphClkInitStruct.PLLSAI.PLLSAIR = 2;
  PeriphClkInitStruct.PLLSAIDivR = RCC_PLLSAIDIVR_2;
  if (HAL_RCCEx_PeriphCLKConfig(&PeriphClkInitStruct) != HAL_OK)
  {
    Error_Handler();
  }
}

static void MX_DMA2D_Init(void)
{

  hdma2d.Instance = DMA2D;
  hdma2d.Init.Mode = DMA2D_M2M;
  hdma2d.Init.ColorMode = DMA2D_OUTPUT_RGB565;
  hdma2d.Init.OutputOffset = 0;
  hdma2d.LayerCfg[1].InputOffset = 0;
  hdma2d.LayerCfg[1].InputColorMode = DMA2D_INPUT_RGB565;
  hdma2d.LayerCfg[1].AlphaMode = DMA2D_NO_MODIF_ALPHA;
  hdma2d.LayerCfg[1].InputAlpha = 0;
  if (HAL_DMA2D_Init(&hdma2d) != HAL_OK)
  {
    Error_Handler();
  }
  if (HAL_DMA2D_ConfigLayer(&hdma2d, 1) != HAL_OK)
  {
    Error_Handler();
  }

}

static void MX_I2C3_Init(void)
{

  hi2c3.Instance = I2C3;
  hi2c3.Init.ClockSpeed = 100000;
  hi2c3.Init.DutyCycle = I2C_DUTYCYCLE_2;
  hi2c3.Init.OwnAddress1 = 0;
  hi2c3.Init.AddressingMode = I2C_ADDRESSINGMODE_7BIT;
  hi2c3.Init.DualAddressMode = I2C_DUALADDRESS_DISABLE;
  hi2c3.Init.OwnAddress2 = 0;
  hi2c3.Init.GeneralCallMode = I2C_GENERALCALL_DISABLE;
  hi2c3.Init.NoStretchMode = I2C_NOSTRETCH_DISABLE;
  if (HAL_I2C_Init(&hi2c3) != HAL_OK)
  {
    Error_Handler();
  }
  /** Configure Analogue filter
  */
  if (HAL_I2CEx_ConfigAnalogFilter(&hi2c3, I2C_ANALOGFILTER_DISABLE) != HAL_OK)
  {
    Error_Handler();
  }
  /** Configure Digital filter
  */
  if (HAL_I2CEx_ConfigDigitalFilter(&hi2c3, 0) != HAL_OK)
  {
    Error_Handler();
  }

}

static void MX_LTDC_Init(void)
{

  LTDC_LayerCfgTypeDef pLayerCfg = {0};

  hltdc.Instance = LTDC;
  hltdc.Init.HSPolarity = LTDC_HSPOLARITY_AL;
  hltdc.Init.VSPolarity = LTDC_VSPOLARITY_AL;
  hltdc.Init.DEPolarity = LTDC_DEPOLARITY_AL;
  hltdc.Init.PCPolarity = LTDC_PCPOLARITY_IPC;
  hltdc.Init.HorizontalSync = 9;
  hltdc.Init.VerticalSync = 1;
  hltdc.Init.AccumulatedHBP = 29;
  hltdc.Init.AccumulatedVBP = 3;
  hltdc.Init.AccumulatedActiveW = 269;
  hltdc.Init.AccumulatedActiveH = 323;
  hltdc.Init.TotalWidth = 279;
  hltdc.Init.TotalHeigh = 327;
  hltdc.Init.Backcolor.Blue = 0;
  hltdc.Init.Backcolor.Green = 0;
  hltdc.Init.Backcolor.Red = 0;
  if (HAL_LTDC_Init(&hltdc) != HAL_OK)
  {
    Error_Handler();
  }
  pLayerCfg.WindowX0 = 0;
  pLayerCfg.WindowX1 = 240;
  pLayerCfg.WindowY0 = 0;
  pLayerCfg.WindowY1 = 320;
  pLayerCfg.PixelFormat = LTDC_PIXEL_FORMAT_RGB565;
  pLayerCfg.Alpha = 255;
  pLayerCfg.Alpha0 = 0;
  pLayerCfg.BlendingFactor1 = LTDC_BLENDING_FACTOR1_CA;
  pLayerCfg.BlendingFactor2 = LTDC_BLENDING_FACTOR2_CA;
  pLayerCfg.FBStartAdress = 0;
  pLayerCfg.ImageWidth = 240;
  pLayerCfg.ImageHeight = 320;
  pLayerCfg.Backcolor.Blue = 0;
  pLayerCfg.Backcolor.Green = 0;
  pLayerCfg.Backcolor.Red = 0;
  if (HAL_LTDC_ConfigLayer(&hltdc, &pLayerCfg, 0) != HAL_OK)
  {
    Error_Handler();
  }

}

static void MX_SPI5_Init(void)
{

  /* SPI5 parameter configuration*/
  hspi5.Instance = SPI5;
  hspi5.Init.Mode = SPI_MODE_MASTER;
  hspi5.Init.Direction = SPI_DIRECTION_2LINES;
  hspi5.Init.DataSize = SPI_DATASIZE_8BIT;
  hspi5.Init.CLKPolarity = SPI_POLARITY_LOW;
  hspi5.Init.CLKPhase = SPI_PHASE_1EDGE;
  hspi5.Init.NSS = SPI_NSS_SOFT;
  hspi5.Init.BaudRatePrescaler = SPI_BAUDRATEPRESCALER_16;
  hspi5.Init.FirstBit = SPI_FIRSTBIT_MSB;
  hspi5.Init.TIMode = SPI_TIMODE_DISABLE;
  hspi5.Init.CRCCalculation = SPI_CRCCALCULATION_DISABLE;
  hspi5.Init.CRCPolynomial = 10;
  if (HAL_SPI_Init(&hspi5) != HAL_OK)
  {
    Error_Handler();
  }

}

static void MX_TIM1_Init(void)
{

  TIM_ClockConfigTypeDef sClockSourceConfig = {0};
  TIM_MasterConfigTypeDef sMasterConfig = {0};

  htim1.Instance = TIM1;
  htim1.Init.Prescaler = 0;
  htim1.Init.CounterMode = TIM_COUNTERMODE_UP;
  htim1.Init.Period = 0;
  htim1.Init.ClockDivision = TIM_CLOCKDIVISION_DIV1;
  htim1.Init.RepetitionCounter = 0;
  htim1.Init.AutoReloadPreload = TIM_AUTORELOAD_PRELOAD_DISABLE;
  if (HAL_TIM_Base_Init(&htim1) != HAL_OK)
  {
    Error_Handler();
  }
  sClockSourceConfig.ClockSource = TIM_CLOCKSOURCE_INTERNAL;
  if (HAL_TIM_ConfigClockSource(&htim1, &sClockSourceConfig) != HAL_OK)
  {
    Error_Handler();
  }
  sMasterConfig.MasterOutputTrigger = TIM_TRGO_RESET;
  sMasterConfig.MasterSlaveMode = TIM_MASTERSLAVEMODE_DISABLE;
  if (HAL_TIMEx_MasterConfigSynchronization(&htim1, &sMasterConfig) != HAL_OK)
  {
    Error_Handler();
  }

}

static void MX_USART1_UART_Init(void)
{

  huart1.Instance = USART1;
  huart1.Init.BaudRate = 115200;
  huart1.Init.WordLength = UART_WORDLENGTH_8B;
  huart1.Init.StopBits = UART_STOPBITS_1;
  huart1.Init.Parity = UART_PARITY_NONE;
  huart1.Init.Mode = UART_MODE_TX_RX;
  huart1.Init.HwFlowCtl = UART_HWCONTROL_NONE;
  huart1.Init.OverSampling = UART_OVERSAMPLING_16;
  if (HAL_UART_Init(&huart1) != HAL_OK)
  {
    Error_Handler();
  }
  /* USER CODE BEGIN USART1_Init 2 */
	SET_BIT(huart1.Instance->CR1, USART_CR1_RXNEIE);
  HAL_NVIC_SetPriority(USART1_IRQn, 0, 0);
  HAL_NVIC_EnableIRQ(USART1_IRQn);
  /* USER CODE END USART1_Init 2 */

}

/* FMC initialization function */
static void MX_FMC_Init(void)
{

  FMC_SDRAM_TimingTypeDef SdramTiming = {0};

  /** Perform the SDRAM1 memory initialization sequence
  */
  hsdram1.Instance = FMC_SDRAM_DEVICE;
  /* hsdram1.Init */
  hsdram1.Init.SDBank = FMC_SDRAM_BANK2;
  hsdram1.Init.ColumnBitsNumber = FMC_SDRAM_COLUMN_BITS_NUM_8;
  hsdram1.Init.RowBitsNumber = FMC_SDRAM_ROW_BITS_NUM_12;
  hsdram1.Init.MemoryDataWidth = FMC_SDRAM_MEM_BUS_WIDTH_16;
  hsdram1.Init.InternalBankNumber = FMC_SDRAM_INTERN_BANKS_NUM_4;
  hsdram1.Init.CASLatency = FMC_SDRAM_CAS_LATENCY_3;
  hsdram1.Init.WriteProtection = FMC_SDRAM_WRITE_PROTECTION_DISABLE;
  hsdram1.Init.SDClockPeriod = FMC_SDRAM_CLOCK_PERIOD_2;
  hsdram1.Init.ReadBurst = FMC_SDRAM_RBURST_DISABLE;
  hsdram1.Init.ReadPipeDelay = FMC_SDRAM_RPIPE_DELAY_1;
  /* SdramTiming */
  SdramTiming.LoadToActiveDelay = 2;
  SdramTiming.ExitSelfRefreshDelay = 7;
  SdramTiming.SelfRefreshTime = 4;
  SdramTiming.RowCycleDelay = 7;
  SdramTiming.WriteRecoveryTime = 3;
  SdramTiming.RPDelay = 2;
  SdramTiming.RCDDelay = 2;

  if (HAL_SDRAM_Init(&hsdram1, &SdramTiming) != HAL_OK)
  {
    Error_Handler( );
  }

}

static void MX_GPIO_Init(void)
{
  GPIO_InitTypeDef GPIO_InitStruct = {0};

  /* GPIO Ports Clock Enable */
  __HAL_RCC_GPIOC_CLK_ENABLE();
  __HAL_RCC_GPIOF_CLK_ENABLE();
  __HAL_RCC_GPIOH_CLK_ENABLE();
  __HAL_RCC_GPIOA_CLK_ENABLE();
  __HAL_RCC_GPIOB_CLK_ENABLE();
  __HAL_RCC_GPIOG_CLK_ENABLE();
  __HAL_RCC_GPIOE_CLK_ENABLE();
  __HAL_RCC_GPIOD_CLK_ENABLE();

  /*Configure GPIO pin Output Level */
  HAL_GPIO_WritePin(GPIOC, GPIO_PIN_1|GPIO_PIN_2|GPIO_PIN_4, GPIO_PIN_RESET);

  /*Configure GPIO pin Output Level */
  HAL_GPIO_WritePin(GPIOA, GPIO_PIN_7, GPIO_PIN_RESET);

  /*Configure GPIO pin Output Level */
  HAL_GPIO_WritePin(GPIOD, GPIO_PIN_12|GPIO_PIN_13, GPIO_PIN_RESET);

  /*Configure GPIO pin Output Level */
  HAL_GPIO_WritePin(GPIOG, GPIO_PIN_13|GPIO_PIN_14, GPIO_PIN_RESET);

  /*Configure GPIO pins : PC1 PC2 PC4 */
  GPIO_InitStruct.Pin = GPIO_PIN_1|GPIO_PIN_2|GPIO_PIN_4;
  GPIO_InitStruct.Mode = GPIO_MODE_OUTPUT_PP;
  GPIO_InitStruct.Pull = GPIO_NOPULL;
  GPIO_InitStruct.Speed = GPIO_SPEED_FREQ_LOW;
  HAL_GPIO_Init(GPIOC, &GPIO_InitStruct);

  /*Configure GPIO pins : PA0 PA1 PA2 PA15 */
  GPIO_InitStruct.Pin = GPIO_PIN_0|GPIO_PIN_1|GPIO_PIN_2|GPIO_PIN_15;
  GPIO_InitStruct.Mode = GPIO_MODE_IT_RISING;
  GPIO_InitStruct.Pull = GPIO_NOPULL;
  HAL_GPIO_Init(GPIOA, &GPIO_InitStruct);

  /*Configure GPIO pin : PA7 */
  GPIO_InitStruct.Pin = GPIO_PIN_7;
  GPIO_InitStruct.Mode = GPIO_MODE_OUTPUT_PP;
  GPIO_InitStruct.Pull = GPIO_NOPULL;
  GPIO_InitStruct.Speed = GPIO_SPEED_FREQ_LOW;
  HAL_GPIO_Init(GPIOA, &GPIO_InitStruct);

  /*Configure GPIO pin : PC5 */
  GPIO_InitStruct.Pin = GPIO_PIN_5;
  GPIO_InitStruct.Mode = GPIO_MODE_IT_RISING;
  GPIO_InitStruct.Pull = GPIO_NOPULL;
  HAL_GPIO_Init(GPIOC, &GPIO_InitStruct);

  /*Configure GPIO pin : PB2 */
  GPIO_InitStruct.Pin = GPIO_PIN_2;
  GPIO_InitStruct.Mode = GPIO_MODE_INPUT;
  GPIO_InitStruct.Pull = GPIO_NOPULL;
  HAL_GPIO_Init(GPIOB, &GPIO_InitStruct);

  /*Configure GPIO pins : PB12 PB14 PB15 */
  GPIO_InitStruct.Pin = GPIO_PIN_12|GPIO_PIN_14|GPIO_PIN_15;
  GPIO_InitStruct.Mode = GPIO_MODE_AF_PP;
  GPIO_InitStruct.Pull = GPIO_NOPULL;
  GPIO_InitStruct.Speed = GPIO_SPEED_FREQ_VERY_HIGH;
  GPIO_InitStruct.Alternate = GPIO_AF12_OTG_HS_FS;
  HAL_GPIO_Init(GPIOB, &GPIO_InitStruct);

  /*Configure GPIO pin : PB13 */
  GPIO_InitStruct.Pin = GPIO_PIN_13;
  GPIO_InitStruct.Mode = GPIO_MODE_INPUT;
  GPIO_InitStruct.Pull = GPIO_NOPULL;
  HAL_GPIO_Init(GPIOB, &GPIO_InitStruct);

  /*Configure GPIO pin : PD11 */
  GPIO_InitStruct.Pin = GPIO_PIN_11;
  GPIO_InitStruct.Mode = GPIO_MODE_INPUT;
  GPIO_InitStruct.Pull = GPIO_NOPULL;
  HAL_GPIO_Init(GPIOD, &GPIO_InitStruct);

  /*Configure GPIO pins : PD12 PD13 */
  GPIO_InitStruct.Pin = GPIO_PIN_12|GPIO_PIN_13;
  GPIO_InitStruct.Mode = GPIO_MODE_OUTPUT_PP;
  GPIO_InitStruct.Pull = GPIO_NOPULL;
  GPIO_InitStruct.Speed = GPIO_SPEED_FREQ_LOW;
  HAL_GPIO_Init(GPIOD, &GPIO_InitStruct);

  /*Configure GPIO pins : PG13 PG14 */
  GPIO_InitStruct.Pin = GPIO_PIN_13|GPIO_PIN_14;
  GPIO_InitStruct.Mode = GPIO_MODE_OUTPUT_PP;
  GPIO_InitStruct.Pull = GPIO_NOPULL;
  GPIO_InitStruct.Speed = GPIO_SPEED_FREQ_LOW;
  HAL_GPIO_Init(GPIOG, &GPIO_InitStruct);

}

/* USER CODE BEGIN 4 */

#ifdef __GNUC__
  /* With GCC/RAISONANCE, small printf (option LD Linker->Libraries->Small printf
     set to 'Yes') calls __io_putchar() */
  #define PUTCHAR_PROTOTYPE int __io_putchar(int ch)
#else
  #define PUTCHAR_PROTOTYPE int fputc(int ch, FILE *f)
#endif /* __GNUC__ */
/**
  * @brief  Retargets the C library printf function to the USART.
  * @param  None
  * @retval None
  */
PUTCHAR_PROTOTYPE
{
  /* write a character to the uart1 and Loop until the end of transmission */
  HAL_UART_Transmit(&huart1, (uint8_t *)&ch, 1, 0xFFFF);

  return ch;
}

/* USER CODE END 4 */

 /**
  * @brief  Period elapsed callback in non blocking mode
  * @note   This function is called  when TIM6 interrupt took place, inside
  * HAL_TIM_IRQHandler(). It makes a direct call to HAL_IncTick() to increment
  * a global variable "uwTick" used as application time base.
  * @param  htim : TIM handle
  * @retval None
  */
void HAL_TIM_PeriodElapsedCallback(TIM_HandleTypeDef *htim)
{
  if (htim->Instance == TIM6) {
    HAL_IncTick();
  }
}

void Error_Handler(void)
{
}

/************************ (C) COPYRIGHT STMicroelectronics *****END OF FILE****/
